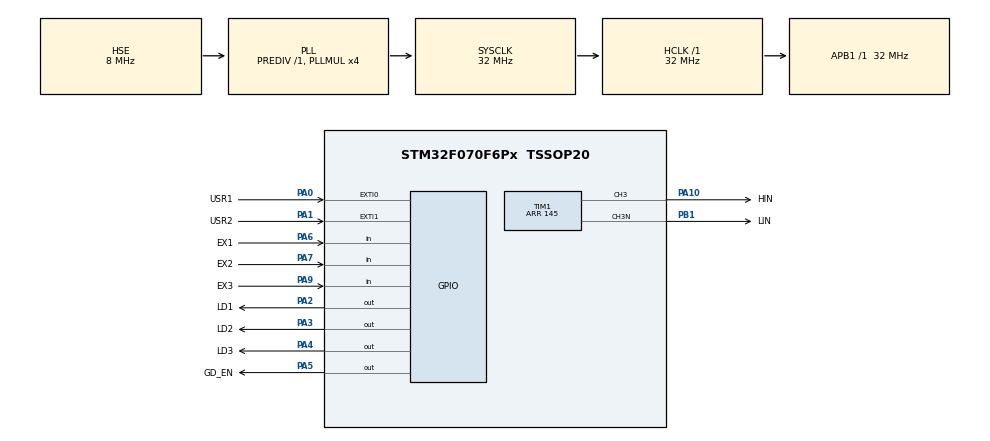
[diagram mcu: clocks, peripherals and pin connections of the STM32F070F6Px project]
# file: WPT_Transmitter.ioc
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Mcu.Family=STM32F0
Mcu.Name=STM32F070F6Px
Mcu.Package=TSSOP20
NVIC.EXTI0_1_IRQn=true\:0\:0\:false\:false\:true\:true\:true
PA0.GPIO_Label=USR1
PA0.GPIO_ModeDefaultEXTI=GPIO_MODE_IT_FALLING
PA0.Signal=GPXTI0
PA1.GPIO_Label=USR2
PA1.GPIO_ModeDefaultEXTI=GPIO_MODE_IT_FALLING
PA1.Signal=GPXTI1
PA10.GPIO_Label=HIN
PA10.Signal=S_TIM1_CH3
PA13.Mode=Serial_Wire
PA13.Signal=SYS_SWDIO
PA14.Mode=Serial_Wire
PA14.Signal=SYS_SWCLK
PA2.GPIO_Label=LD1
PA2.Signal=GPIO_Output
PA3.GPIO_Label=LD2
PA3.Signal=GPIO_Output
PA4.GPIO_Label=LD3
PA4.Signal=GPIO_Output
PA5.GPIO_Label=GD_EN
PA5.Signal=GPIO_Output
PA6.GPIO_Label=EX1
PA6.Signal=GPIO_Input
PA7.GPIO_Label=EX2
PA7.Signal=GPIO_Input
PA9.GPIO_Label=EX3
PA9.Signal=GPIO_Input
PB1.GPIO_Label=LIN
PB1.Mode=PWM Generation3 CH3 CH3N
PB1.Signal=TIM1_CH3N
PF0-OSC_IN.Mode=HSE-External-Oscillator
PF0-OSC_IN.Signal=RCC_OSC_IN
PF1-OSC_OUT.Mode=HSE-External-Oscillator
PF1-OSC_OUT.Signal=RCC_OSC_OUT
ProjectManager.HeapSize=0x200
ProjectManager.StackSize=0x400
ProjectManager.TargetToolchain=MDK-ARM V5
RCC.AHBFreq_Value=32000000
RCC.APB1Freq_Value=32000000
RCC.APB1TimFreq_Value=32000000
RCC.HCLKFreq_Value=32000000
RCC.PLLMUL=RCC_PLL_MUL4
RCC.PLLSourceVirtual=RCC_PLLSOURCE_HSE
RCC.SYSCLKFreq_VALUE=32000000
RCC.SYSCLKSource=RCC_SYSCLKSOURCE_PLLCLK
SH.S_TIM1_CH3.0=TIM1_CH3,PWM Generation3 CH3 CH3N
TIM1.Channel-PWM\ Generation3\ CH3\ CH3N=TIM_CHANNEL_3
TIM1.DeadTime=7
TIM1.Period=145
TIM1.Pulse-PWM\ Generation3\ CH3\ CH3N=73
VP_TIM1_VS_ClockSourceINT.Mode=Internal
board=custom

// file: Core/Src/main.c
/* USER CODE BEGIN Header */
/**
  ******************************************************************************
  * @file           : main.c
  * @brief          : Main program body
  ******************************************************************************
  * @attention
  *
  * <h2><center>&copy; Copyright (c) 2020 STMicroelectronics.
  * All rights reserved.</center></h2>
  *
  * This software component is licensed by ST under BSD 3-Clause license,
  * the "License"; You may not use this file except in compliance with the
  * License. You may obtain a copy of the License at:
  *                        opensource.org/licenses/BSD-3-Clause
  *
  ******************************************************************************
  */
/* USER CODE END Header */
#include "main.h"

TIM_HandleTypeDef htim1;

void SystemClock_Config(void);
static void MX_GPIO_Init(void);
static void MX_TIM1_Init(void);

int main(void)
{

  /* MCU Configuration--------------------------------------------------------*/

  /* Reset of all peripherals, Initializes the Flash interface and the Systick. */
  HAL_Init();

  /* Configure the system clock */
  SystemClock_Config();

  /* Initialize all configured peripherals */
  MX_GPIO_Init();
  MX_TIM1_Init();
  /* USER CODE BEGIN 2 */
	HAL_GPIO_WritePin(GPIOA, GPIO_PIN_5, GPIO_PIN_RESET);
	HAL_TIM_PWM_Start(&htim1, TIM_CHANNEL_3);
	HAL_TIMEx_PWMN_Start(&htim1, TIM_CHANNEL_3);
  /* USER CODE END 2 */

  /* Infinite loop */
  while (1)
  {

    /* USER CODE BEGIN 3 */
		HAL_GPIO_TogglePin(GPIOA, GPIO_PIN_2);
		HAL_Delay(500);
  }
  /* USER CODE END 3 */
}

void SystemClock_Config(void)
{
  RCC_OscInitTypeDef RCC_OscInitStruct = {0};
  RCC_ClkInitTypeDef RCC_ClkInitStruct = {0};

  /** Initializes the RCC Oscillators according to the specified parameters
  * in the RCC_OscInitTypeDef structure.
  */
  RCC_OscInitStruct.OscillatorType = RCC_OSCILLATORTYPE_HSE;
  RCC_OscInitStruct.HSEState = RCC_HSE_ON;
  RCC_OscInitStruct.PLL.PLLState = RCC_PLL_ON;
  RCC_OscInitStruct.PLL.PLLSource = RCC_PLLSOURCE_HSE;
  RCC_OscInitStruct.PLL.PLLMUL = RCC_PLL_MUL4;
  RCC_OscInitStruct.PLL.PREDIV = RCC_PREDIV_DIV1;
  if (HAL_RCC_OscConfig(&RCC_OscInitStruct) != HAL_OK)
  {
    Error_Handler();
  }
  /** Initializes the CPU, AHB and APB buses clocks
  */
  RCC_ClkInitStruct.ClockType = RCC_CLOCKTYPE_HCLK|RCC_CLOCKTYPE_SYSCLK
                              |RCC_CLOCKTYPE_PCLK1;
  RCC_ClkInitStruct.SYSCLKSource = RCC_SYSCLKSOURCE_PLLCLK;
  RCC_ClkInitStruct.AHBCLKDivider = RCC_SYSCLK_DIV1;
  RCC_ClkInitStruct.APB1CLKDivider = RCC_HCLK_DIV1;

  if (HAL_RCC_ClockConfig(&RCC_ClkInitStruct, FLASH_LATENCY_1) != HAL_OK)
  {
    Error_Handler();
  }
}

static void MX_TIM1_Init(void)
{

  TIM_ClockConfigTypeDef sClockSourceConfig = {0};
  TIM_MasterConfigTypeDef sMasterConfig = {0};
  TIM_OC_InitTypeDef sConfigOC = {0};
  TIM_BreakDeadTimeConfigTypeDef sBreakDeadTimeConfig = {0};

  htim1.Instance = TIM1;
  htim1.Init.Prescaler = 0;
  htim1.Init.CounterMode = TIM_COUNTERMODE_UP;
  htim1.Init.Period = 145;
  htim1.Init.ClockDivision = TIM_CLOCKDIVISION_DIV1;
  htim1.Init.RepetitionCounter = 0;
  htim1.Init.AutoReloadPreload = TIM_AUTORELOAD_PRELOAD_DISABLE;
  if (HAL_TIM_Base_Init(&htim1) != HAL_OK)
  {
    Error_Handler();
  }
  sClockSourceConfig.ClockSource = TIM_CLOCKSOURCE_INTERNAL;
  if (HAL_TIM_ConfigClockSource(&htim1, &sClockSourceConfig) != HAL_OK)
  {
    Error_Handler();
  }
  if (HAL_TIM_PWM_Init(&htim1) != HAL_OK)
  {
    Error_Handler();
  }
  sMasterConfig.MasterOutputTrigger = TIM_TRGO_RESET;
  sMasterConfig.MasterSlaveMode = TIM_MASTERSLAVEMODE_DISABLE;
  if (HAL_TIMEx_MasterConfigSynchronization(&htim1, &sMasterConfig) != HAL_OK)
  {
    Error_Handler();
  }
  sConfigOC.OCMode = TIM_OCMODE_PWM1;
  sConfigOC.Pulse = 73;
  sConfigOC.OCPolarity = TIM_OCPOLARITY_HIGH;
  sConfigOC.OCNPolarity = TIM_OCNPOLARITY_HIGH;
  sConfigOC.OCFastMode = TIM_OCFAST_DISABLE;
  sConfigOC.OCIdleState = TIM_OCIDLESTATE_RESET;
  sConfigOC.OCNIdleState = TIM_OCNIDLESTATE_RESET;
  if (HAL_TIM_PWM_ConfigChannel(&htim1, &sConfigOC, TIM_CHANNEL_3) != HAL_OK)
  {
    Error_Handler();
  }
  sBreakDeadTimeConfig.OffStateRunMode = TIM_OSSR_DISABLE;
  sBreakDeadTimeConfig.OffStateIDLEMode = TIM_OSSI_DISABLE;
  sBreakDeadTimeConfig.LockLevel = TIM_LOCKLEVEL_OFF;
  sBreakDeadTimeConfig.DeadTime = 7;
  sBreakDeadTimeConfig.BreakState = TIM_BREAK_DISABLE;
  sBreakDeadTimeConfig.BreakPolarity = TIM_BREAKPOLARITY_HIGH;
  sBreakDeadTimeConfig.AutomaticOutput = TIM_AUTOMATICOUTPUT_DISABLE;
  if (HAL_TIMEx_ConfigBreakDeadTime(&htim1, &sBreakDeadTimeConfig) != HAL_OK)
  {
    Error_Handler();
  }
  HAL_TIM_MspPostInit(&htim1);

}

static void MX_GPIO_Init(void)
{
  GPIO_InitTypeDef GPIO_InitStruct = {0};

  /* GPIO Ports Clock Enable */
  __HAL_RCC_GPIOF_CLK_ENABLE();
  __HAL_RCC_GPIOA_CLK_ENABLE();
  __HAL_RCC_GPIOB_CLK_ENABLE();

  /*Configure GPIO pin Output Level */
  HAL_GPIO_WritePin(GPIOA, LD1_Pin|LD2_Pin|LD3_Pin|GD_EN_Pin, GPIO_PIN_RESET);

  /*Configure GPIO pins : USR1_Pin USR2_Pin */
  GPIO_InitStruct.Pin = USR1_Pin|USR2_Pin;
  GPIO_InitStruct.Mode = GPIO_MODE_IT_FALLING;
  GPIO_InitStruct.Pull = GPIO_NOPULL;
  HAL_GPIO_Init(GPIOA, &GPIO_InitStruct);

  /*Configure GPIO pins : LD1_Pin LD2_Pin LD3_Pin GD_EN_Pin */
  GPIO_InitStruct.Pin = LD1_Pin|LD2_Pin|LD3_Pin|GD_EN_Pin;
  GPIO_InitStruct.Mode = GPIO_MODE_OUTPUT_PP;
  GPIO_InitStruct.Pull = GPIO_NOPULL;
  GPIO_InitStruct.Speed = GPIO_SPEED_FREQ_LOW;
  HAL_GPIO_Init(GPIOA, &GPIO_InitStruct);

  /*Configure GPIO pins : EX1_Pin EX2_Pin EX3_Pin */
  GPIO_InitStruct.Pin = EX1_Pin|EX2_Pin|EX3_Pin;
  GPIO_InitStruct.Mode = GPIO_MODE_INPUT;
  GPIO_InitStruct.Pull = GPIO_NOPULL;
  HAL_GPIO_Init(GPIOA, &GPIO_InitStruct);

  /* EXTI interrupt init*/
  HAL_NVIC_SetPriority(EXTI0_1_IRQn, 0, 0);
  HAL_NVIC_EnableIRQ(EXTI0_1_IRQn);

}

/* USER CODE BEGIN 4 */

void HAL_GPIO_EXTI_Callback(uint16_t GPIO_Pin)
{
	if(GPIO_Pin == GPIO_PIN_0)
	{
		HAL_GPIO_WritePin(GPIOA, GPIO_PIN_3, GPIO_PIN_SET);
	}
	else if(GPIO_Pin == USR2_Pin)
	{
		HAL_GPIO_WritePin(LD2_GPIO_Port, LD2_Pin, GPIO_PIN_RESET);
	}
}

/* USER CODE END 4 */

void Error_Handler(void)
{
  __disable_irq();
  while (1)
  {
  }
}

/************************ (C) COPYRIGHT STMicroelectronics *****END OF FILE****/
